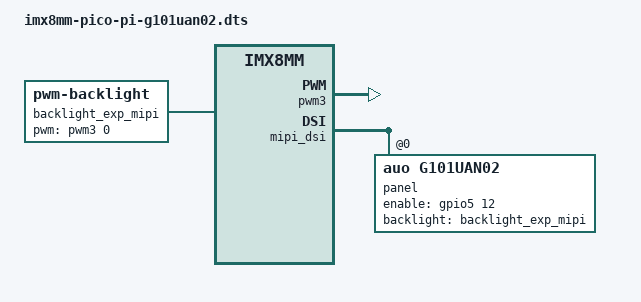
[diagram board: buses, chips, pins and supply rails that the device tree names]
/*
 * Copyright 2018 Technexion Ltd.
 * Copyright 2018 NXP
 *
 * Author: Richard Hu <richard.hu@technexion.com>
 *
 * This program is free software; you can redistribute it and/or
 * modify it under the terms of the GNU General Public License
 * as published by the Free Software Foundation; either version 2
 * of the License, or (at your option) any later version.
 *
 * This program is distributed in the hope that it will be useful,
 * but WITHOUT ANY WARRANTY; without even the implied warranty of
 * MERCHANTABILITY or FITNESS FOR A PARTICULAR PURPOSE.  See the
 * GNU General Public License for more details.
 */

#if 0
#include "imx8mm-pico-pi.dts"

/ {
	backlight_mipi: backlight_mipi{
		status = "okay";
	};
};

#if 0 // simple panel driver
&mipi_dsi {
	status = "okay";

	panel@0 {
		// compatible = "bananapi,lhr050h41", "ilitek,ili9881c";
		// compatible = "auo,g080uan01";
		compatible = "auo,g101uan02";
		pinctrl-0 = <&pinctrl_mipi_dsi_rst>;
		// enable-gpios = <&gpio3 9 GPIO_ACTIVE_LOW>;
		backlight = <&backlight_mipi>;

		//reset-gpio = <&gpio3 9 GPIO_ACTIVE_LOW>;
		reg = <0>;
		dsi-lanes = <4>;
		status = "okay";
	};
};
#else
&mipi_dsi {
	status = "okay";

	panel@0 {
		//compatible = "bananapi,lhr050h41", "ilitek,ili9881c";
		// compatible = "auo,g080uan01";
		compatible = "auo,g101uan02";
		pinctrl-0 = <&pinctrl_mipi_dsi_rst>;
		// enable-gpios = <&gpio3 9 GPIO_ACTIVE_LOW>;
		backlight = <&backlight_mipi>;
		// reset-gpio = <&gpio3 9 GPIO_ACTIVE_LOW>;
		// reg = <0>;
		// dsi-lanes = <4>;
		status = "okay";
	};
};
#endif

&i2c3 {
	polytouch: edt-ft5x06@38 {
		compatible = "edt,edt-ft5x06";
		reg = <0x38>;
		pinctrl-names = "default";
		pinctrl-0 = <&pinctrl_touch_irq &pinctrl_touch_rst>;
		interrupt-parent = <&gpio1>;
		interrupts = <7 IRQ_TYPE_EDGE_FALLING>;
		reset-gpios = <&gpio4 28 GPIO_ACTIVE_LOW>;
		touchscreen-size-x = <720>;
		touchscreen-size-y = <1280>;
	};
};

#else


/*
 * Copyright 2018 Technexion Ltd.
 * Copyright 2018 NXP
 *
 * Author: Richard Hu <richard.hu@technexion.com>
 *
 * This program is free software; you can redistribute it and/or
 * modify it under the terms of the GNU General Public License
 * as published by the Free Software Foundation; either version 2
 * of the License, or (at your option) any later version.
 *
 * This program is distributed in the hope that it will be useful,
 * but WITHOUT ANY WARRANTY; without even the implied warranty of
 * MERCHANTABILITY or FITNESS FOR A PARTICULAR PURPOSE.  See the
 * GNU General Public License for more details.
 */

//#include "pico-imx8mm.dts"

#include "imx8mm-pico-pi.dts"


/ {
       backlight_exp_mipi: backlight_exp_mipi {
               compatible = "pwm-backlight";
               pwms = <&pwm3 0 50000 0>;
               brightness-levels = <0 36 72 108 144 180 216 255>;
               default-brightness-level = <6>;
               status = "okay";
       };
};

&iomuxc {
       pinctrl-names = "default";

       imx8mm-pico {
               pinctrl_exp_dsi_pwm: exp_dsi_pwm {
                       fsl,pins = <
                               MX8MM_IOMUXC_SPDIF_TX_PWM3_OUT          0x16    /* Expansion DSI PWM */
                       >;
               };

               pinctrl_exp_mipi_dsi_en: exp_mipi_dsi_en {
                       fsl,pins = <
                               MX8MM_IOMUXC_ECSPI2_MISO_GPIO5_IO12     0x16   /* Enable pin for MIPI DSI panel */
                       >;
               };
       };
};

&pwm3 {
       pinctrl-names = "default";
       pinctrl-0 = <&pinctrl_exp_dsi_pwm>;
       status = "okay";
};

&mipi_dsi {
       status = "okay";

       panel@0 {
               compatible = "auo,g101uan02";
               reg = <0>;
               pinctrl-0 = <&pinctrl_exp_mipi_dsi_en>;
               enable-gpios = <&gpio5 12 GPIO_ACTIVE_HIGH>;
               backlight = <&backlight_exp_mipi>;
               status = "okay";
       };
};

#endif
